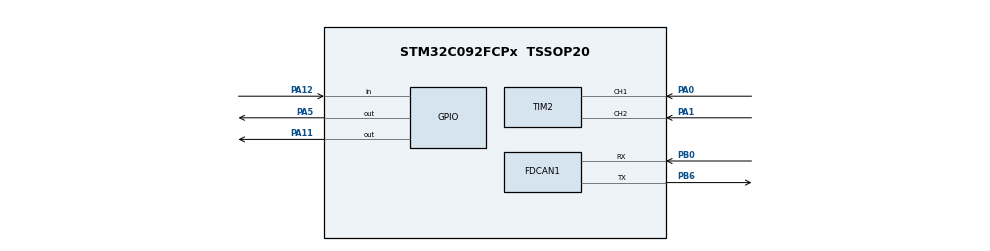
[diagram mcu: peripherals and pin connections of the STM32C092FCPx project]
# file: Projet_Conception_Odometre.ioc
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FDCAN1.CalculateBaudRateNominal=250000
FDCAN1.CalculateTimeBitNominal=4000
FDCAN1.CalculateTimeQuantumNominal=1333.3333333333333
Mcu.Family=STM32C0
Mcu.Name=STM32C092FCPx
Mcu.Package=TSSOP20
NVIC.TIM2_IRQn=true\:0\:0\:false\:false\:true\:true\:true\:true
PA0.Signal=S_TIM2_CH1
PA1.Signal=S_TIM2_CH2
PA11\ [PA9].Signal=GPIO_Output
PA12\ [PA10].Signal=GPIO_Input
PA13.Mode=Serial_Wire
PA13.Signal=DEBUG_SWDIO
PA14-BOOT0.Mode=Serial_Wire
PA14-BOOT0.Signal=DEBUG_SWCLK
PA14-BOOT0__PA15.StandardMode=true
PA2.Signal=USART2_TX
PA3.Signal=USART2_RX
PA5.Signal=GPIO_Output
PB0.Mode=FDCAN_Activate
PB0.Signal=FDCAN1_RX
PB0__PB1__PB2__PA8.StandardMode=true
PB3__PB4__PB5__PB6.StandardMode=true
PB6.Mode=FDCAN_Activate
PB6.Signal=FDCAN1_TX
PB7__PB8.StandardMode=true
ProjectManager.HeapSize=0x200
ProjectManager.StackSize=0x400
ProjectManager.TargetToolchain=STM32CubeIDE
RCC.ADCFreq_Value=12000000
RCC.AHBFreq_Value=12000000
RCC.CortexFreq_Value=12000000
RCC.EXTERNAL_CLOCK_VALUE=12288000
RCC.HCLKFreq_Value=12000000
RCC.HSE_VALUE=8000000
RCC.HSI_VALUE=48000000
RCC.LSE_VALUE=32768
RCC.SYSCLKFreq_VALUE=12000000
SH.S_TIM2_CH1.0=TIM2_CH1,Encoder_Interface
SH.S_TIM2_CH2.0=TIM2_CH2,Encoder_Interface
board=custom

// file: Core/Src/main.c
/* USER CODE BEGIN Header */
/**
  ******************************************************************************
  * @file           : main.c
  * @brief          : Main program body
  ******************************************************************************
  * @attention
  *
  * Copyright (c) 2026 STMicroelectronics.
  * All rights reserved.
  *
  * This software is licensed under terms that can be found in the LICENSE file
  * in the root directory of this software component.
  * If no LICENSE file comes with this software, it is provided AS-IS.
  *
  ******************************************************************************
  */
/* USER CODE END Header */
#include "main.h"

FDCAN_HandleTypeDef hfdcan1;

TIM_HandleTypeDef htim2;

void SystemClock_Config(void);
static void MX_GPIO_Init(void);
static void MX_FDCAN1_Init(void);
static void MX_TIM2_Init(void);

int main(void)
{

  /* MCU Configuration--------------------------------------------------------*/

  /* Reset of all peripherals, Initializes the Flash interface and the Systick. */
  HAL_Init();

  /* Configure the system clock */
  SystemClock_Config();

  /* Initialize all configured peripherals */
  MX_GPIO_Init();
  MX_FDCAN1_Init();
  MX_TIM2_Init();

  /* Infinite loop */
  /* USER CODE BEGIN WHILE */
  void setup();
  while (1)
  {
	  void loop();
    /* USER CODE END WHILE */

  }
}

void SystemClock_Config(void)
{
  RCC_OscInitTypeDef RCC_OscInitStruct = {0};
  RCC_ClkInitTypeDef RCC_ClkInitStruct = {0};

  __HAL_FLASH_SET_LATENCY(FLASH_LATENCY_0);

  /** Initializes the RCC Oscillators according to the specified parameters
  * in the RCC_OscInitTypeDef structure.
  */
  RCC_OscInitStruct.OscillatorType = RCC_OSCILLATORTYPE_HSI;
  RCC_OscInitStruct.HSIState = RCC_HSI_ON;
  RCC_OscInitStruct.HSIDiv = RCC_HSI_DIV4;
  RCC_OscInitStruct.HSICalibrationValue = RCC_HSICALIBRATION_DEFAULT;
  if (HAL_RCC_OscConfig(&RCC_OscInitStruct) != HAL_OK)
  {
    Error_Handler();
  }

  /** Initializes the CPU, AHB and APB buses clocks
  */
  RCC_ClkInitStruct.ClockType = RCC_CLOCKTYPE_HCLK|RCC_CLOCKTYPE_SYSCLK
                              |RCC_CLOCKTYPE_PCLK1;
  RCC_ClkInitStruct.SYSCLKSource = RCC_SYSCLKSOURCE_HSI;
  RCC_ClkInitStruct.SYSCLKDivider = RCC_SYSCLK_DIV1;
  RCC_ClkInitStruct.AHBCLKDivider = RCC_HCLK_DIV1;
  RCC_ClkInitStruct.APB1CLKDivider = RCC_APB1_DIV1;

  if (HAL_RCC_ClockConfig(&RCC_ClkInitStruct, FLASH_LATENCY_0) != HAL_OK)
  {
    Error_Handler();
  }
}

static void MX_FDCAN1_Init(void)
{

  hfdcan1.Instance = FDCAN1;
  hfdcan1.Init.ClockDivider = FDCAN_CLOCK_DIV1;
  hfdcan1.Init.FrameFormat = FDCAN_FRAME_CLASSIC;
  hfdcan1.Init.Mode = FDCAN_MODE_NORMAL;
  hfdcan1.Init.AutoRetransmission = DISABLE;
  hfdcan1.Init.TransmitPause = DISABLE;
  hfdcan1.Init.ProtocolException = DISABLE;
  hfdcan1.Init.NominalPrescaler = 16;
  hfdcan1.Init.NominalSyncJumpWidth = 1;
  hfdcan1.Init.NominalTimeSeg1 = 1;
  hfdcan1.Init.NominalTimeSeg2 = 1;
  hfdcan1.Init.DataPrescaler = 1;
  hfdcan1.Init.DataSyncJumpWidth = 1;
  hfdcan1.Init.DataTimeSeg1 = 1;
  hfdcan1.Init.DataTimeSeg2 = 1;
  hfdcan1.Init.StdFiltersNbr = 0;
  hfdcan1.Init.ExtFiltersNbr = 0;
  hfdcan1.Init.TxFifoQueueMode = FDCAN_TX_FIFO_OPERATION;
  if (HAL_FDCAN_Init(&hfdcan1) != HAL_OK)
  {
    Error_Handler();
  }

}

static void MX_TIM2_Init(void)
{

  TIM_Encoder_InitTypeDef sConfig = {0};
  TIM_MasterConfigTypeDef sMasterConfig = {0};

  htim2.Instance = TIM2;
  htim2.Init.Prescaler = 0;
  htim2.Init.CounterMode = TIM_COUNTERMODE_UP;
  htim2.Init.Period = 4294967295;
  htim2.Init.ClockDivision = TIM_CLOCKDIVISION_DIV1;
  htim2.Init.AutoReloadPreload = TIM_AUTORELOAD_PRELOAD_DISABLE;
  sConfig.EncoderMode = TIM_ENCODERMODE_TI1;
  sConfig.IC1Polarity = TIM_ICPOLARITY_RISING;
  sConfig.IC1Selection = TIM_ICSELECTION_DIRECTTI;
  sConfig.IC1Prescaler = TIM_ICPSC_DIV1;
  sConfig.IC1Filter = 0;
  sConfig.IC2Polarity = TIM_ICPOLARITY_RISING;
  sConfig.IC2Selection = TIM_ICSELECTION_DIRECTTI;
  sConfig.IC2Prescaler = TIM_ICPSC_DIV1;
  sConfig.IC2Filter = 0;
  if (HAL_TIM_Encoder_Init(&htim2, &sConfig) != HAL_OK)
  {
    Error_Handler();
  }
  sMasterConfig.MasterOutputTrigger = TIM_TRGO_RESET;
  sMasterConfig.MasterSlaveMode = TIM_MASTERSLAVEMODE_DISABLE;
  if (HAL_TIMEx_MasterConfigSynchronization(&htim2, &sMasterConfig) != HAL_OK)
  {
    Error_Handler();
  }

}

static void MX_GPIO_Init(void)
{
  GPIO_InitTypeDef GPIO_InitStruct = {0};

  /* GPIO Ports Clock Enable */
  __HAL_RCC_GPIOA_CLK_ENABLE();
  __HAL_RCC_GPIOB_CLK_ENABLE();

  /*Configure GPIO pin Output Level */
  HAL_GPIO_WritePin(GPIOA, GPIO_PIN_5|GPIO_PIN_11, GPIO_PIN_RESET);

  /*Configure GPIO pins : PA2 PA3 */
  GPIO_InitStruct.Pin = GPIO_PIN_2|GPIO_PIN_3;
  GPIO_InitStruct.Mode = GPIO_MODE_AF_PP;
  GPIO_InitStruct.Pull = GPIO_NOPULL;
  GPIO_InitStruct.Speed = GPIO_SPEED_FREQ_LOW;
  GPIO_InitStruct.Alternate = GPIO_AF1_USART2;
  HAL_GPIO_Init(GPIOA, &GPIO_InitStruct);

  /*Configure GPIO pins : PA5 PA11 */
  GPIO_InitStruct.Pin = GPIO_PIN_5|GPIO_PIN_11;
  GPIO_InitStruct.Mode = GPIO_MODE_OUTPUT_PP;
  GPIO_InitStruct.Pull = GPIO_NOPULL;
  GPIO_InitStruct.Speed = GPIO_SPEED_FREQ_LOW;
  HAL_GPIO_Init(GPIOA, &GPIO_InitStruct);

  /*Configure GPIO pin : PA12 */
  GPIO_InitStruct.Pin = GPIO_PIN_12;
  GPIO_InitStruct.Mode = GPIO_MODE_INPUT;
  GPIO_InitStruct.Pull = GPIO_NOPULL;
  HAL_GPIO_Init(GPIOA, &GPIO_InitStruct);

}

void Error_Handler(void)
{
  __disable_irq();
  while (1)
  {
  }
}
